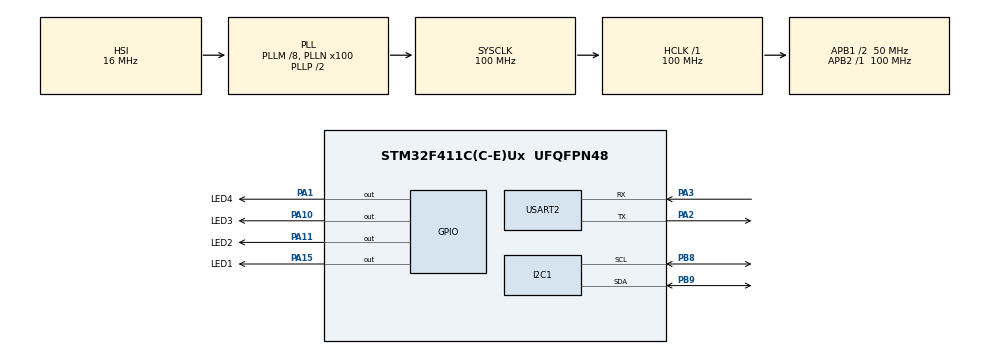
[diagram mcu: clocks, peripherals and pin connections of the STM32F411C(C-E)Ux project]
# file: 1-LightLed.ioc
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Dma.Request0=USART2_TX
Dma.USART2_TX.0.Direction=DMA_MEMORY_TO_PERIPH
Dma.USART2_TX.0.FIFOMode=DMA_FIFOMODE_DISABLE
Dma.USART2_TX.0.Instance=DMA1_Stream6
Dma.USART2_TX.0.MemDataAlignment=DMA_MDATAALIGN_BYTE
Dma.USART2_TX.0.MemInc=DMA_MINC_ENABLE
Dma.USART2_TX.0.Mode=DMA_NORMAL
Dma.USART2_TX.0.PeriphDataAlignment=DMA_PDATAALIGN_BYTE
Dma.USART2_TX.0.PeriphInc=DMA_PINC_DISABLE
Dma.USART2_TX.0.Priority=DMA_PRIORITY_LOW
I2C1.I2C_Mode=I2C_Fast
Mcu.Family=STM32F4
Mcu.Name=STM32F411C(C-E)Ux
Mcu.Package=UFQFPN48
NVIC.DMA1_Stream6_IRQn=true\:0\:0\:false\:false\:true\:false\:false
NVIC.PriorityGroup=NVIC_PRIORITYGROUP_4
NVIC.TIM1_TRG_COM_TIM11_IRQn=true\:0\:0\:false\:false\:true\:false\:true
NVIC.TimeBase=TIM1_TRG_COM_TIM11_IRQn
NVIC.TimeBaseIP=TIM11
PA1.GPIO_Label=LED4
PA1.GPIO_ModeDefaultOutputPP=GPIO_MODE_OUTPUT_PP
PA1.GPIO_PuPd=GPIO_NOPULL
PA1.GPIO_Speed=GPIO_SPEED_FREQ_LOW
PA1.PinState=GPIO_PIN_RESET
PA1.Signal=GPIO_Output
PA10.GPIO_Label=LED3
PA10.GPIO_ModeDefaultOutputPP=GPIO_MODE_OUTPUT_PP
PA10.GPIO_PuPd=GPIO_NOPULL
PA10.GPIO_Speed=GPIO_SPEED_FREQ_LOW
PA10.PinState=GPIO_PIN_RESET
PA10.Signal=GPIO_Output
PA11.GPIO_Label=LED2
PA11.GPIO_ModeDefaultOutputPP=GPIO_MODE_OUTPUT_PP
PA11.GPIO_PuPd=GPIO_NOPULL
PA11.GPIO_Speed=GPIO_SPEED_FREQ_LOW
PA11.PinState=GPIO_PIN_RESET
PA11.Signal=GPIO_Output
PA15.GPIO_Label=LED1
PA15.GPIO_ModeDefaultOutputPP=GPIO_MODE_OUTPUT_PP
PA15.GPIO_PuPd=GPIO_NOPULL
PA15.GPIO_Speed=GPIO_SPEED_FREQ_LOW
PA15.PinState=GPIO_PIN_RESET
PA15.Signal=GPIO_Output
PA2.Mode=Asynchronous
PA2.Signal=USART2_TX
PA3.Mode=Asynchronous
PA3.Signal=USART2_RX
PB8.Mode=I2C
PB8.Signal=I2C1_SCL
PB9.Mode=I2C
PB9.Signal=I2C1_SDA
PH0\ -\ OSC_IN.Mode=HSE-External-Clock-Source
PH0\ -\ OSC_IN.Signal=RCC_OSC_IN
PH1\ -\ OSC_OUT.Mode=HSE-External-Clock-Source
PH1\ -\ OSC_OUT.Signal=RCC_OSC_OUT
ProjectManager.HeapSize=0x400
ProjectManager.StackSize=0x400
ProjectManager.TargetToolchain=MDK-ARM V5
RCC.48MHZClocksFreq_Value=50000000
RCC.AHBFreq_Value=100000000
RCC.APB1CLKDivider=RCC_HCLK_DIV2
RCC.APB1Freq_Value=50000000
RCC.APB1TimFreq_Value=100000000
RCC.APB2Freq_Value=100000000
RCC.APB2TimFreq_Value=100000000
RCC.CortexFreq_Value=100000000
RCC.HCLKFreq_Value=100000000
RCC.HSE_VALUE=25000000
RCC.HSI_VALUE=16000000
RCC.LSE_VALUE=32768
RCC.PLLM=8
RCC.PLLN=100
RCC.SYSCLKFreq_VALUE=100000000
RCC.SYSCLKSource=RCC_SYSCLKSOURCE_PLLCLK
RCC.VCOOutputFreq_Value=200000000
USART2.VirtualMode=VM_ASYNC
VP_SYS_VS_tim11.Mode=TIM11
board=custom

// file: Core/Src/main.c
/* USER CODE BEGIN Header */
/**
  ******************************************************************************
  * @file           : main.c
  * @brief          : Main program body
  ******************************************************************************
  * @attention
  *
  * <h2><center>&copy; Copyright (c) 2019 STMicroelectronics.
  * All rights reserved.</center></h2>
  *
  * This software component is licensed by ST under BSD 3-Clause license,
  * the "License"; You may not use this file except in compliance with the
  * License. You may obtain a copy of the License at:
  *                        opensource.org/licenses/BSD-3-Clause
  *
  ******************************************************************************
  */
/* USER CODE END Header */

#include "main.h"
#include "dma.h"
#include "i2c.h"
#include "usart.h"
#include "gpio.h"

/* USER CODE BEGIN Includes */
#include "stdio.h"
#include "rtx_main.h"

/* USER CODE END Includes */

void SystemClock_Config(void);

int main(void)
{

  /* MCU Configuration--------------------------------------------------------*/

  /* Reset of all peripherals, Initializes the Flash interface and the Systick. */
  HAL_Init();

  /* Configure the system clock */
  SystemClock_Config();

  /* Initialize all configured peripherals */
  MX_GPIO_Init();
  MX_I2C1_Init();
  MX_USART2_UART_Init();
  MX_DMA_Init();
  /* USER CODE BEGIN 2 */
	rtx_main();
  /* USER CODE END 2 */

  /* Infinite loop */
    while (1)
    {

    }
}

void SystemClock_Config(void)
{
  RCC_OscInitTypeDef RCC_OscInitStruct = {0};
  RCC_ClkInitTypeDef RCC_ClkInitStruct = {0};

  /** Configure the main internal regulator output voltage
  */
  __HAL_RCC_PWR_CLK_ENABLE();
  __HAL_PWR_VOLTAGESCALING_CONFIG(PWR_REGULATOR_VOLTAGE_SCALE1);
  /** Initializes the CPU, AHB and APB busses clocks
  */
  RCC_OscInitStruct.OscillatorType = RCC_OSCILLATORTYPE_HSI;
  RCC_OscInitStruct.HSIState = RCC_HSI_ON;
  RCC_OscInitStruct.HSICalibrationValue = RCC_HSICALIBRATION_DEFAULT;
  RCC_OscInitStruct.PLL.PLLState = RCC_PLL_ON;
  RCC_OscInitStruct.PLL.PLLSource = RCC_PLLSOURCE_HSI;
  RCC_OscInitStruct.PLL.PLLM = 8;
  RCC_OscInitStruct.PLL.PLLN = 100;
  RCC_OscInitStruct.PLL.PLLP = RCC_PLLP_DIV2;
  RCC_OscInitStruct.PLL.PLLQ = 4;
  if (HAL_RCC_OscConfig(&RCC_OscInitStruct) != HAL_OK)
  {
    Error_Handler();
  }
  /** Initializes the CPU, AHB and APB busses clocks
  */
  RCC_ClkInitStruct.ClockType = RCC_CLOCKTYPE_HCLK|RCC_CLOCKTYPE_SYSCLK
                              |RCC_CLOCKTYPE_PCLK1|RCC_CLOCKTYPE_PCLK2;
  RCC_ClkInitStruct.SYSCLKSource = RCC_SYSCLKSOURCE_PLLCLK;
  RCC_ClkInitStruct.AHBCLKDivider = RCC_SYSCLK_DIV1;
  RCC_ClkInitStruct.APB1CLKDivider = RCC_HCLK_DIV2;
  RCC_ClkInitStruct.APB2CLKDivider = RCC_HCLK_DIV1;

  if (HAL_RCC_ClockConfig(&RCC_ClkInitStruct, FLASH_LATENCY_3) != HAL_OK)
  {
    Error_Handler();
  }
}

void HAL_TIM_PeriodElapsedCallback(TIM_HandleTypeDef *htim)
{
  if (htim->Instance == TIM11) {
    HAL_IncTick();
  }
}

void Error_Handler(void)
{
}

/************************ (C) COPYRIGHT STMicroelectronics *****END OF FILE****/
